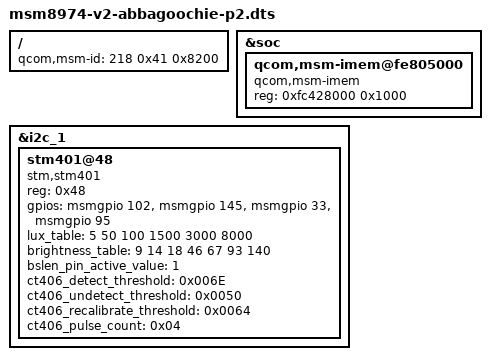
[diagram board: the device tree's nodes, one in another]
/* Copyright (c) 2013 Motorola Mobility LLC
 *
 * This program is free software; you can redistribute it and/or modify
 * it under the terms of the GNU General Public License version 2 and
 * only version 2 as published by the Free Software Foundation.
 *
 * This program is distributed in the hope that it will be useful,
 * but WITHOUT ANY WARRANTY; without even the implied warranty of
 * MERCHANTABILITY or FITNESS FOR A PARTICULAR PURPOSE.  See the
 * GNU General Public License for more details.
 */

/dts-v1/;
/include/ "msm8974-moto-reserve.dtsi"
/include/ "msm8974-v2-abbagoochie-common.dtsi"


/ {
	qcom,msm-id = <218 0x41 0x8200>;
};

&soc {
	qcom,msm-imem@fe805000 {
		compatible = "qcom,msm-imem";
		reg = <0xfc428000 0x1000>; /* Address and size of IMEM */
	};
};

&i2c_1 {
        stm401@48 {
                compatible = "stm,stm401";
                reg = <0x48>;
                gpios = <&msmgpio 102 0>,        /* IRQ */
                        <&msmgpio 145 0>,       /* RESET */
                        <&msmgpio 33 0>,        /* BSLEN */
                        <&msmgpio 95 0>;        /* WakeIRQ */
                lux_table = <5 50 100 1500 3000 8000>;
                brightness_table = <9 14 18 46 67 93 140>;
                bslen_pin_active_value = <1>;
                ct406_detect_threshold = <0x006E>;
                ct406_undetect_threshold = <0x0050>;
                ct406_recalibrate_threshold = <0x0064>;
                ct406_pulse_count = <0x04>;
        };
};
